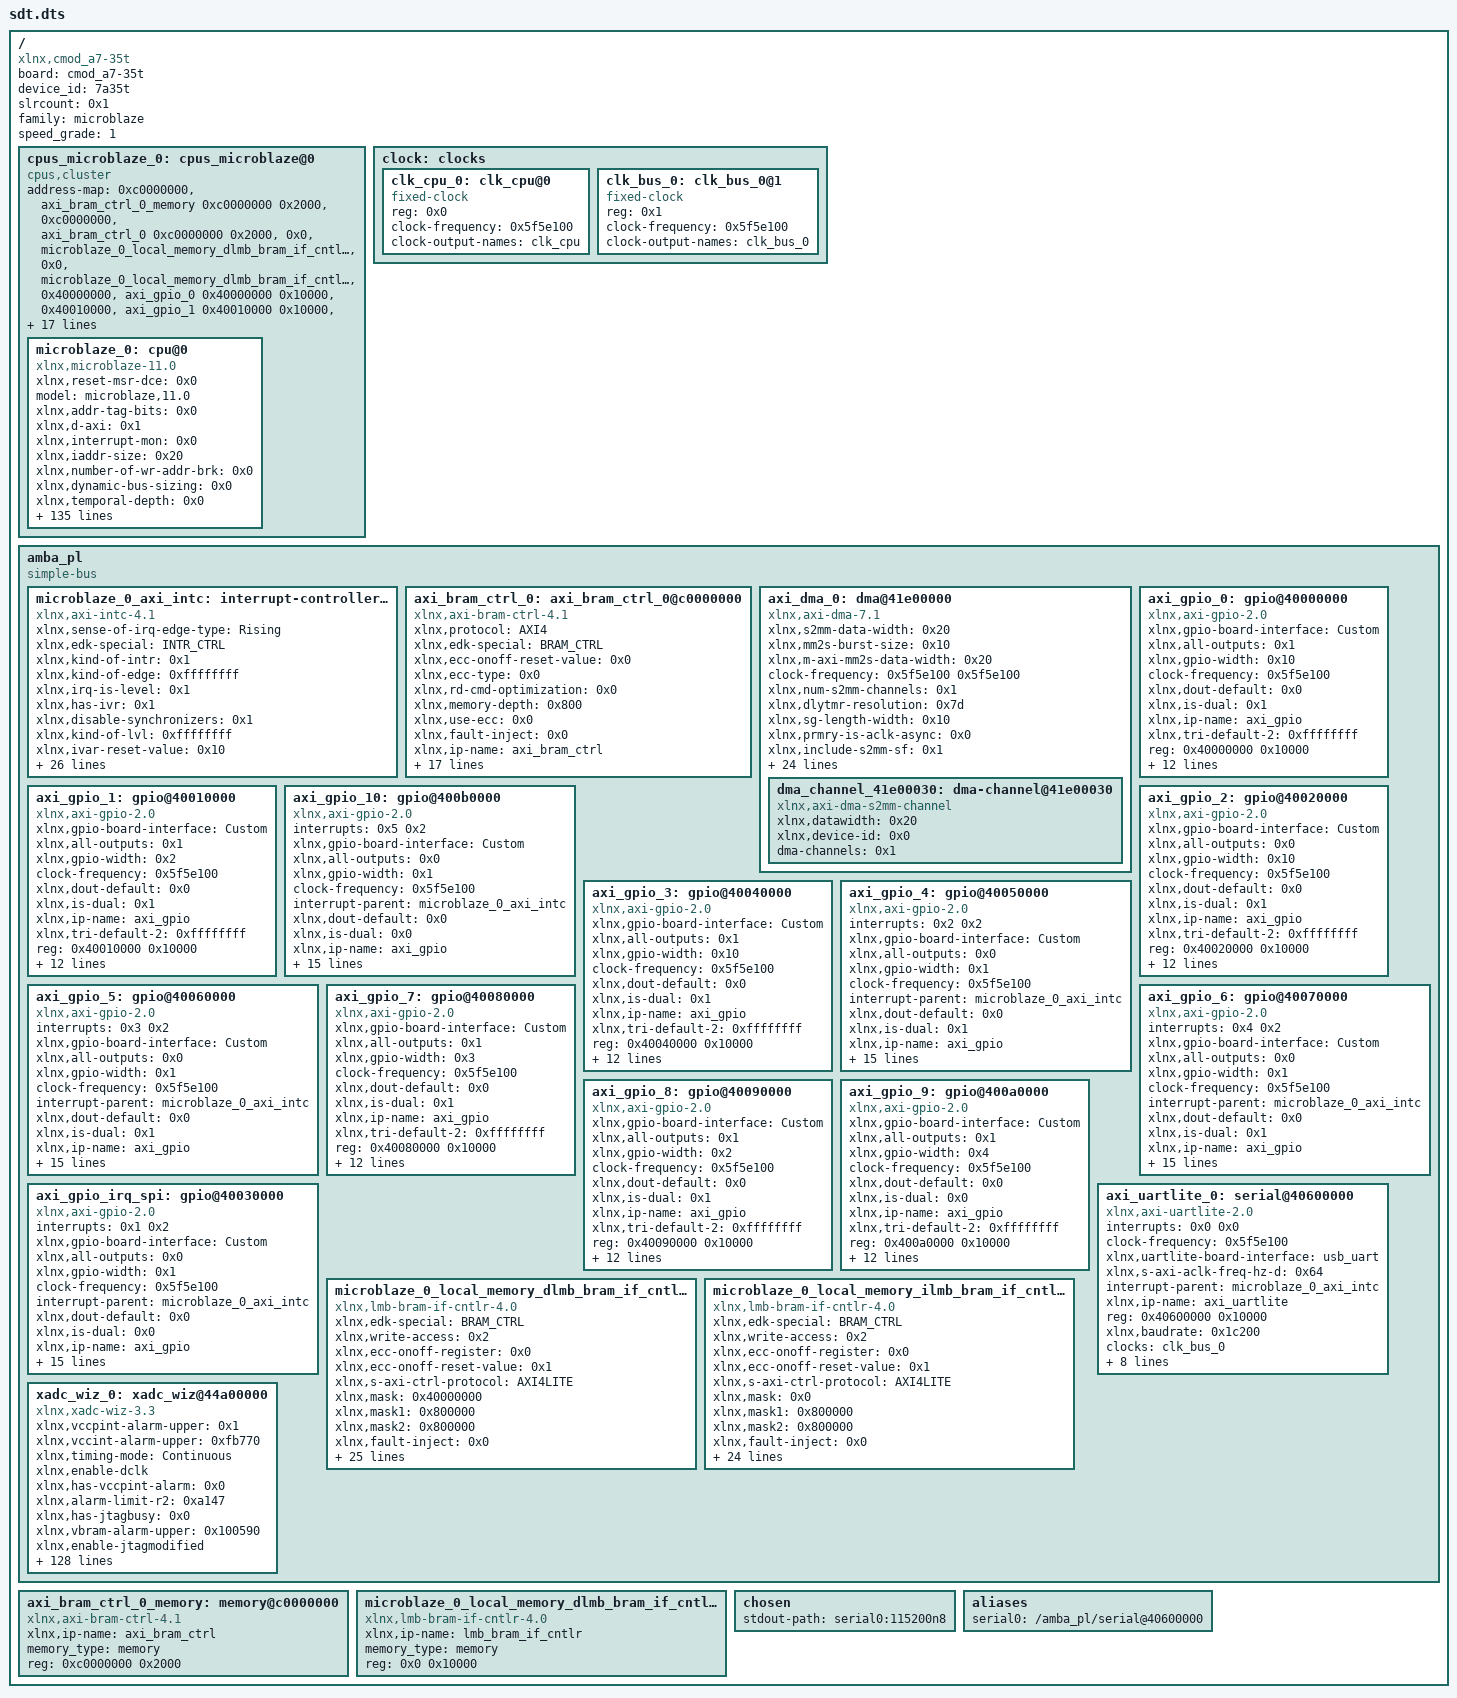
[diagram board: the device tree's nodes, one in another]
/dts-v1/;
/ {
        board = "cmod_a7-35t";
        compatible = "xlnx,cmod_a7-35t";
        device_id = "7a35t";
        #address-cells = <0x1>;
        #size-cells = <0x1>;
        slrcount = <0x1>;
        family = "microblaze";
        speed_grade = "1";

        cpus_microblaze_0: cpus_microblaze@0 {
                #cpu-mask-cells = <0x1>;
                compatible = "cpus,cluster";
                #address-cells = <0x1>;
                #size-cells = <0x0>;
                address-map = <0xc0000000 &axi_bram_ctrl_0_memory 0xc0000000 0x2000>,
                 <0xc0000000 &axi_bram_ctrl_0 0xc0000000 0x2000>,
                 <0x0 &microblaze_0_local_memory_dlmb_bram_if_cntlr_memory 0x0 0x10000>,
                 <0x0 &microblaze_0_local_memory_dlmb_bram_if_cntlr 0x0 0x10000>,
                 <0x40000000 &axi_gpio_0 0x40000000 0x10000>,
                 <0x40010000 &axi_gpio_1 0x40010000 0x10000>,
                 <0x40020000 &axi_gpio_2 0x40020000 0x10000>,
                 <0x40030000 &axi_gpio_irq_spi 0x40030000 0x10000>,
                 <0x40040000 &axi_gpio_3 0x40040000 0x10000>,
                 <0x40050000 &axi_gpio_4 0x40050000 0x10000>,
                 <0x40060000 &axi_gpio_5 0x40060000 0x10000>,
                 <0x40070000 &axi_gpio_6 0x40070000 0x10000>,
                 <0x40080000 &axi_gpio_7 0x40080000 0x10000>,
                 <0x40090000 &axi_gpio_8 0x40090000 0x10000>,
                 <0x400a0000 &axi_gpio_9 0x400a0000 0x10000>,
                 <0x400b0000 &axi_gpio_10 0x400b0000 0x10000>,
                 <0x40600000 &axi_uartlite_0 0x40600000 0x10000>,
                 <0x41200000 &microblaze_0_axi_intc 0x41200000 0x10000>,
                 <0x41e00000 &axi_dma_0 0x41e00000 0x10000>,
                 <0x44a00000 &xadc_wiz_0 0x44a00000 0x10000>;
                #ranges-address-cells = <0x1>;
                #ranges-size-cells = <0x1>;
                phandle = <0x17>;

                microblaze_0: cpu@0 {
                        xlnx,reset-msr-dce = <0x0>;
                        model = "microblaze,11.0";
                        xlnx,addr-tag-bits = <0x0>;
                        xlnx,d-axi = <0x1>;
                        xlnx,interrupt-mon = <0x0>;
                        xlnx,iaddr-size = <0x20>;
                        xlnx,number-of-wr-addr-brk = <0x0>;
                        xlnx,dynamic-bus-sizing = <0x0>;
                        xlnx,temporal-depth = <0x0>;
                        xlnx,use-interrupt = <0x2>;
                        xlnx,optimization = <0x0>;
                        xlnx,ip-axi-mon = <0x0>;
                        xlnx,ip-name = "microblaze";
                        d-cache-highaddr = <0x3fffffff>;
                        xlnx,dcache-force-tag-lutram = <0x0>;
                        xlnx,pc-width = <0x20>;
                        xlnx,interrupt-is-edge = <0x0>;
                        reg = <0x0>;
                        xlnx,async-interrupt = <0x1>;
                        xlnx,use-mmu = <0x0>;
                        xlnx,reset-msr-ee = <0x0>;
                        xlnx,icache-victims = <0x0>;
                        xlnx,use-reorder-instr = <0x1>;
                        xlnx,d-lmb-mon = <0x0>;
                        xlnx,d-lmb-protocol = <0x0>;
                        xlnx,ill-opcode-exception = <0x0>;
                        xlnx,dcache-always-used = <0x1>;
                        xlnx,use-div = <0x0>;
                        xlnx,dc-axi-mon = <0x0>;
                        xlnx,debug-trace-async-reset = <0x0>;
                        xlnx,trace = <0x0>;
                        xlnx,part = "xc7a35tcpg236-1";
                        i-cache-baseaddr = <0x0>;
                        xlnx,use-config-reset = <0x0>;
                        xlnx,pvr = <0x0>;
                        xlnx,i-lmb-mon = <0x0>;
                        xlnx,dcache-byte-size = <0x2000>;
                        xlnx,fault-tolerant = <0x0>;
                        xlnx,family = "artix7";
                        compatible = "xlnx,microblaze-11.0", "xlnx,microblaze";
                        xlnx,data-size = <0x20>;
                        xlnx,mmu-zones = <0x10>;
                        xlnx,debug-trace-size = <0x2000>;
                        xlnx,mmu-privileged-instr = <0x0>;
                        xlnx,enable-discrete-ports = <0x0>;
                        d-cache-line-size = <0x10>;
                        xlnx,d-lmb = <0x1>;
                        xlnx,sco = <0x0>;
                        xlnx,reset-msr-eip = <0x0>;
                        xlnx,debug-interface = <0x0>;
                        clock-frequency = <0x5f5e100>;
                        xlnx,use-ext-brk = <0x0>;
                        xlnx,daddr-size = <0x20>;
                        xlnx,debug-enabled = <0x1>;
                        xlnx,reset-msr-ice = <0x0>;
                        xlnx,num-sync-ff-dbg-trace-clk = <0x2>;
                        xlnx,i-lmb-protocol = <0x0>;
                        xlnx,endianness = <0x1>;
                        xlnx,fsl-exception = <0x0>;
                        i-cache-line-size = <0x10>;
                        xlnx,use-extended-fsl-instr = <0x0>;
                        xlnx,reset-msr = <0x0>;
                        xlnx,dp-axi-mon = <0x0>;
                        device_type = "cpu";
                        xlnx,branch-target-cache-size = <0x0>;
                        xlnx,dcache-use-writeback = <0x0>;
                        xlnx,div-zero-exception = <0x0>;
                        xlnx,mmu-tlb-access = <0x3>;
                        bus-handle = <0x15>;
                        xlnx,cache-byte-size = <0x2000>;
                        xlnx,pvr-user2 = <0x0>;
                        xlnx,opcode-0x0-illegal = <0x0>;
                        xlnx,icache-line-len = <0x4>;
                        xlnx,ecc-use-ce-exception = <0x0>;
                        xlnx,base-vectors = <0x0>;
                        xlnx,edk-special = "microblaze";
                        xlnx,use-dcache = <0x0>;
                        xlnx,use-barrel = <0x0>;
                        xlnx,reset-msr-bip = <0x0>;
                        xlnx,allow-dcache-wr = <0x1>;
                        xlnx,debug-external-trace = <0x0>;
                        xlnx,addr-size = <0x20>;
                        xlnx,piaddr-size = <0x20>;
                        i-cache-highaddr = <0x3fffffff>;
                        xlnx,num-sync-ff-clk-debug = <0x2>;
                        xlnx,debug-event-counters = <0x5>;
                        xlnx,fpu-exception = <0x0>;
                        xlnx,allow-icache-wr = <0x1>;
                        xlnx,g-use-exceptions = <0x0>;
                        xlnx,i-axi = <0x0>;
                        xlnx,g-template-list = <0x0>;
                        xlnx,icache-streams = <0x0>;
                        xlnx,dcache-line-len = <0x4>;
                        xlnx,num-sync-ff-clk = <0x2>;
                        xlnx,edk-iptype = "PROCESSOR";
                        xlnx,use-stack-protection = <0x0>;
                        xlnx,use-hw-mul = <0x0>;
                        xlnx,num-sync-ff-dbg-clk = <0x1>;
                        xlnx,interconnect = <0x2>;
                        xlnx,debug-latency-counters = <0x1>;
                        i-cache-size = <0x2000>;
                        xlnx,exceptions-in-delay-slots = <0x1>;
                        xlnx,use-fpu = <0x0>;
                        xlnx,reset-msr-ie = <0x0>;
                        xlnx,edge-is-positive = <0x1>;
                        xlnx,use-pcmp-instr = <0x0>;
                        xlnx,use-icache = <0x0>;
                        d-cache-size = <0x2000>;
                        xlnx,memory-ip-list = "microblaze_0_local_memory_ilmb_bram_if_cntlr_memory", "microblaze_0_local_memory_dlmb_bram_if_cntlr_memory";
                        xlnx,async-wakeup = <0x3>;
                        xlnx,use-non-secure = <0x0>;
                        xlnx,dcache-addr-tag = <0x0>;
                        xlnx,number-of-rd-addr-brk = <0x0>;
                        d-cache-baseaddr = <0x0>;
                        xlnx,area-optimized = <0x0>;
                        xlnx,avoid-primitives = <0x0>;
                        xlnx,lockstep-slave = <0x0>;
                        xlnx,use-ext-nm-brk = <0x0>;
                        xlnx,instr-size = <0x20>;
                        interrupt-handle = <0x12>;
                        xlnx,icache-always-used = <0x1>;
                        xlnx,i-lmb = <0x1>;
                        xlnx,mmu-dtlb-size = <0x4>;
                        xlnx,lockstep-select = <0x0>;
                        xlnx,lmb-data-size = <0x20>;
                        xlnx,ic-axi-mon = <0x0>;
                        xlnx,enable-conversion = <0x0>;
                        xlnx,num-sync-ff-clk-irq = <0x1>;
                        xlnx,fsl-links = <0x0>;
                        timebase-frequency = <0x5f5e100>;
                        xlnx,icache-force-tag-lutram = <0x0>;
                        xlnx,dcache-data-width = <0x0>;
                        xlnx,dcache-victims = <0x0>;
                        xlnx,use-branch-target-cache = <0x0>;
                        xlnx,debug-profile-size = <0x0>;
                        xlnx,unaligned-exceptions = <0x0>;
                        xlnx,lockstep-master = <0x0>;
                        xlnx,freq = <0x5f5e100>;
                        xlnx,number-of-pc-brk = <0x1>;
                        xlnx,mmu-itlb-size = <0x2>;
                        xlnx,imprecise-exceptions = <0x0>;
                        xlnx,use-msr-instr = <0x0>;
                        xlnx,icache-data-width = <0x0>;
                        xlnx,debug-counter-width = <0x20>;
                        phandle = <0x18>;
                };
        };

        clock: clocks {
                #address-cells = <0x1>;
                #size-cells = <0x0>;
                phandle = <0x19>;

                clk_cpu_0: clk_cpu@0 {
                        compatible = "fixed-clock";
                        reg = <0x0>;
                        clock-frequency = <0x5f5e100>;
                        clock-output-names = "clk_cpu";
                        #clock-cells = <0x0>;
                        phandle = <0x1a>;
                };

                clk_bus_0: clk_bus_0@1 {
                        compatible = "fixed-clock";
                        reg = <0x1>;
                        clock-frequency = <0x5f5e100>;
                        clock-output-names = "clk_bus_0";
                        #clock-cells = <0x0>;
                        phandle = <0x16>;
                };
        };

        amba_pl: amba_pl {
                ranges;
                compatible = "simple-bus";
                #address-cells = <0x1>;
                #size-cells = <0x1>;
                phandle = <0x15>;

                microblaze_0_axi_intc: interrupt-controller@41200000 {
                        #interrupt-cells = <0x2>;
                        xlnx,sense-of-irq-edge-type = "Rising";
                        xlnx,edk-special = "INTR_CTRL";
                        xlnx,kind-of-intr = <0x1>;
                        xlnx,kind-of-edge = <0xffffffff>;
                        xlnx,irq-is-level = <0x1>;
                        xlnx,has-ivr = <0x1>;
                        compatible = "xlnx,axi-intc-4.1", "xlnx,xps-intc-1.00.a";
                        xlnx,disable-synchronizers = <0x1>;
                        xlnx,kind-of-lvl = <0xffffffff>;
                        xlnx,ivar-reset-value = <0x10>;
                        xlnx,irq-active = <0x1>;
                        xlnx,en-cascade-mode = <0x0>;
                        xlnx,ip-name = "axi_intc";
                        xlnx,has-ilr = <0x0>;
                        reg = <0x41200000 0x10000>;
                        xlnx,addr-width = <0x20>;
                        xlnx,s-axi-aclk-freq-mhz = <0x64>;
                        xlnx,num-sw-intr = <0x0>;
                        xlnx,irq-connection = <0x0>;
                        xlnx,num-intr-inputs = <0x6>;
                        xlnx,has-sie = <0x1>;
                        xlnx,enable-async = <0x0>;
                        xlnx,has-cie = <0x1>;
                        xlnx,num-sync-ff = <0x2>;
                        xlnx,edk-iptype = "PERIPHERAL";
                        xlnx,mb-clk-not-connected = <0x1>;
                        xlnx,has-ipr = <0x1>;
                        xlnx,sense-of-irq-level-type = "Active_High";
                        xlnx,cascade-master = <0x0>;
                        xlnx,processor-clk-freq-mhz = <0x64>;
                        status = "okay";
                        xlnx,is-fast = <0x1>;
                        xlnx,has-fast = <0x1>;
                        xlnx,ivar-rst-val = <0x10>;
                        interrupt-controller;
                        xlnx,async-intr = <0xffffffc0>;
                        xlnx,name = "microblaze_0_axi_intc";
                        phandle = <0x12>;
                };

                axi_bram_ctrl_0: axi_bram_ctrl_0@c0000000 {
                        xlnx,protocol = "AXI4";
                        xlnx,edk-special = "BRAM_CTRL";
                        compatible = "xlnx,axi-bram-ctrl-4.1", "xlnx,axi-bram-ctrl";
                        xlnx,ecc-onoff-reset-value = <0x0>;
                        xlnx,ecc-type = <0x0>;
                        xlnx,rd-cmd-optimization = <0x0>;
                        xlnx,memory-depth = <0x800>;
                        xlnx,use-ecc = <0x0>;
                        xlnx,fault-inject = <0x0>;
                        xlnx,ip-name = "axi_bram_ctrl";
                        reg = <0xc0000000 0x2000>;
                        xlnx,bmg-instance = "EXTERNAL";
                        xlnx,s-axi-ctrl-addr-width = <0x20>;
                        xlnx,read-latency = <0x1>;
                        xlnx,id-width = <0x0>;
                        xlnx,s-axi-supports-narrow-burst = <0x0>;
                        xlnx,supports-narrow-burst = <0x0>;
                        xlnx,single-port-bram = <0x0>;
                        xlnx,ecc = <0x0>;
                        xlnx,edk-iptype = "PERIPHERAL";
                        status = "okay";
                        xlnx,data-width = <0x20>;
                        xlnx,bram-addr-width = <0xb>;
                        xlnx,bram-inst-mode = "EXTERNAL";
                        xlnx,s-axi-ctrl-data-width = <0x20>;
                        xlnx,mem-depth = <0x800>;
                        xlnx,s-axi-id-width = <0x1>;
                        xlnx,name = "axi_bram_ctrl_0";
                        phandle = <0x2>;
                };

                axi_dma_0: dma@41e00000 {
                        compatible = "xlnx,axi-dma-7.1", "xlnx,axi-dma-1.00.a";
                        xlnx,s2mm-data-width = <0x20>;
                        xlnx,mm2s-burst-size = <0x10>;
                        xlnx,m-axi-mm2s-data-width = <0x20>;
                        clock-frequency = <0x5f5e100 0x5f5e100>;
                        xlnx,num-s2mm-channels = <0x1>;
                        xlnx,dlytmr-resolution = <0x7d>;
                        xlnx,sg-length-width = <0x10>;
                        xlnx,prmry-is-aclk-async = <0x0>;
                        xlnx,include-s2mm-sf = <0x1>;
                        #dma-cells = <0x1>;
                        xlnx,ip-name = "axi_dma";
                        xlnx,single-interface = <0x0>;
                        xlnx,sg-include-stscntrl-strm = <0x0>;
                        xlnx,include-s2mm-dre = <0x0>;
                        reg = <0x41e00000 0x10000>;
                        xlnx,addr-width = <0x20>;
                        xlnx,include-s2mm = <0x1>;
                        clocks = <&clk_bus_0>,
                         <&clk_bus_0>;
                        xlnx,s-axis-s2mm-tdata-width = <0x20>;
                        xlnx,micro-dma = <0x0>;
                        xlnx,increase-throughput = <0x0>;
                        xlnx,mm2s-data-width = <0x20>;
                        xlnx,addrwidth = <0x20>;
                        xlnx,sg-use-stsapp-length = <0x0>;
                        xlnx,m-axis-mm2s-tdata-width = <0x20>;
                        xlnx,edk-iptype = "PERIPHERAL";
                        xlnx,s2mm-burst-size = <0x10>;
                        xlnx,m-axi-s2mm-data-width = <0x20>;
                        xlnx,num-mm2s-channels = <0x1>;
                        xlnx,enable-multi-channel = <0x0>;
                        status = "okay";
                        xlnx,include-mm2s-sf = <0x1>;
                        clock-names = "s_axi_lite_aclk", "m_axi_sg_aclk", "m_axi_s2mm_aclk";
                        xlnx,include-mm2s = <0x0>;
                        xlnx,include-mm2s-dre = <0x0>;
                        xlnx,name = "axi_dma_0";
                        phandle = <0x13>;

                        dma_channel_41e00030: dma-channel@41e00030 {
                                xlnx,datawidth = <0x20>;
                                xlnx,device-id = <0x0>;
                                compatible = "xlnx,axi-dma-s2mm-channel";
                                dma-channels = <0x1>;
                                phandle = <0x1b>;
                        };
                };

                axi_gpio_0: gpio@40000000 {
                        xlnx,gpio-board-interface = "Custom";
                        compatible = "xlnx,axi-gpio-2.0", "xlnx,xps-gpio-1.00.a";
                        xlnx,all-outputs = <0x1>;
                        #gpio-cells = <0x2>;
                        xlnx,gpio-width = <0x10>;
                        clock-frequency = <0x5f5e100>;
                        xlnx,dout-default = <0x0>;
                        xlnx,is-dual = <0x1>;
                        xlnx,ip-name = "axi_gpio";
                        xlnx,tri-default-2 = <0xffffffff>;
                        reg = <0x40000000 0x10000>;
                        xlnx,all-inputs-2 = <0x0>;
                        clocks = <&clk_bus_0>;
                        xlnx,all-outputs-2 = <0x1>;
                        gpio-controller;
                        xlnx,interrupt-present = <0x0>;
                        xlnx,gpio2-board-interface = "Custom";
                        xlnx,edk-iptype = "PERIPHERAL";
                        xlnx,dout-default-2 = <0x0>;
                        status = "okay";
                        xlnx,gpio2-width = <0x10>;
                        clock-names = "s_axi_aclk";
                        xlnx,tri-default = <0xffffffff>;
                        xlnx,name = "axi_gpio_0";
                        xlnx,all-inputs = <0x0>;
                        phandle = <0x5>;
                };

                axi_gpio_1: gpio@40010000 {
                        xlnx,gpio-board-interface = "Custom";
                        compatible = "xlnx,axi-gpio-2.0", "xlnx,xps-gpio-1.00.a";
                        xlnx,all-outputs = <0x1>;
                        #gpio-cells = <0x2>;
                        xlnx,gpio-width = <0x2>;
                        clock-frequency = <0x5f5e100>;
                        xlnx,dout-default = <0x0>;
                        xlnx,is-dual = <0x1>;
                        xlnx,ip-name = "axi_gpio";
                        xlnx,tri-default-2 = <0xffffffff>;
                        reg = <0x40010000 0x10000>;
                        xlnx,all-inputs-2 = <0x0>;
                        clocks = <&clk_bus_0>;
                        xlnx,all-outputs-2 = <0x1>;
                        gpio-controller;
                        xlnx,interrupt-present = <0x0>;
                        xlnx,gpio2-board-interface = "Custom";
                        xlnx,edk-iptype = "PERIPHERAL";
                        xlnx,dout-default-2 = <0x0>;
                        status = "okay";
                        xlnx,gpio2-width = <0x2>;
                        clock-names = "s_axi_aclk";
                        xlnx,tri-default = <0xffffffff>;
                        xlnx,name = "axi_gpio_1";
                        xlnx,all-inputs = <0x0>;
                        phandle = <0x6>;
                };

                axi_gpio_10: gpio@400b0000 {
                        #interrupt-cells = <0x2>;
                        interrupts = <0x5 0x2>;
                        xlnx,gpio-board-interface = "Custom";
                        compatible = "xlnx,axi-gpio-2.0", "xlnx,xps-gpio-1.00.a";
                        xlnx,all-outputs = <0x0>;
                        #gpio-cells = <0x2>;
                        xlnx,gpio-width = <0x1>;
                        clock-frequency = <0x5f5e100>;
                        interrupt-parent = <&microblaze_0_axi_intc>;
                        xlnx,dout-default = <0x0>;
                        xlnx,is-dual = <0x0>;
                        xlnx,ip-name = "axi_gpio";
                        xlnx,tri-default-2 = <0xffffffff>;
                        reg = <0x400b0000 0x10000>;
                        xlnx,all-inputs-2 = <0x0>;
                        clocks = <&clk_bus_0>;
                        xlnx,all-outputs-2 = <0x0>;
                        gpio-controller;
                        xlnx,interrupt-present = <0x1>;
                        xlnx,gpio2-board-interface = "Custom";
                        xlnx,edk-iptype = "PERIPHERAL";
                        xlnx,dout-default-2 = <0x0>;
                        status = "okay";
                        xlnx,gpio2-width = <0x20>;
                        clock-names = "s_axi_aclk";
                        interrupt-controller;
                        interrupt-names = "ip2intc_irpt";
                        xlnx,tri-default = <0xffffffff>;
                        xlnx,name = "axi_gpio_10";
                        xlnx,all-inputs = <0x1>;
                        phandle = <0x10>;
                };

                axi_gpio_2: gpio@40020000 {
                        xlnx,gpio-board-interface = "Custom";
                        compatible = "xlnx,axi-gpio-2.0", "xlnx,xps-gpio-1.00.a";
                        xlnx,all-outputs = <0x0>;
                        #gpio-cells = <0x2>;
                        xlnx,gpio-width = <0x10>;
                        clock-frequency = <0x5f5e100>;
                        xlnx,dout-default = <0x0>;
                        xlnx,is-dual = <0x1>;
                        xlnx,ip-name = "axi_gpio";
                        xlnx,tri-default-2 = <0xffffffff>;
                        reg = <0x40020000 0x10000>;
                        xlnx,all-inputs-2 = <0x0>;
                        clocks = <&clk_bus_0>;
                        xlnx,all-outputs-2 = <0x1>;
                        gpio-controller;
                        xlnx,interrupt-present = <0x0>;
                        xlnx,gpio2-board-interface = "Custom";
                        xlnx,edk-iptype = "PERIPHERAL";
                        xlnx,dout-default-2 = <0x0>;
                        status = "okay";
                        xlnx,gpio2-width = <0x10>;
                        clock-names = "s_axi_aclk";
                        xlnx,tri-default = <0xffffffff>;
                        xlnx,name = "axi_gpio_2";
                        xlnx,all-inputs = <0x1>;
                        phandle = <0x7>;
                };

                axi_gpio_3: gpio@40040000 {
                        xlnx,gpio-board-interface = "Custom";
                        compatible = "xlnx,axi-gpio-2.0", "xlnx,xps-gpio-1.00.a";
                        xlnx,all-outputs = <0x1>;
                        #gpio-cells = <0x2>;
                        xlnx,gpio-width = <0x10>;
                        clock-frequency = <0x5f5e100>;
                        xlnx,dout-default = <0x0>;
                        xlnx,is-dual = <0x1>;
                        xlnx,ip-name = "axi_gpio";
                        xlnx,tri-default-2 = <0xffffffff>;
                        reg = <0x40040000 0x10000>;
                        xlnx,all-inputs-2 = <0x0>;
                        clocks = <&clk_bus_0>;
                        xlnx,all-outputs-2 = <0x1>;
                        gpio-controller;
                        xlnx,interrupt-present = <0x0>;
                        xlnx,gpio2-board-interface = "Custom";
                        xlnx,edk-iptype = "PERIPHERAL";
                        xlnx,dout-default-2 = <0x0>;
                        status = "okay";
                        xlnx,gpio2-width = <0x10>;
                        clock-names = "s_axi_aclk";
                        xlnx,tri-default = <0xffffffff>;
                        xlnx,name = "axi_gpio_3";
                        xlnx,all-inputs = <0x0>;
                        phandle = <0x9>;
                };

                axi_gpio_4: gpio@40050000 {
                        #interrupt-cells = <0x2>;
                        interrupts = <0x2 0x2>;
                        xlnx,gpio-board-interface = "Custom";
                        compatible = "xlnx,axi-gpio-2.0", "xlnx,xps-gpio-1.00.a";
                        xlnx,all-outputs = <0x0>;
                        #gpio-cells = <0x2>;
                        xlnx,gpio-width = <0x1>;
                        clock-frequency = <0x5f5e100>;
                        interrupt-parent = <&microblaze_0_axi_intc>;
                        xlnx,dout-default = <0x0>;
                        xlnx,is-dual = <0x1>;
                        xlnx,ip-name = "axi_gpio";
                        xlnx,tri-default-2 = <0xffffffff>;
                        reg = <0x40050000 0x10000>;
                        xlnx,all-inputs-2 = <0x1>;
                        clocks = <&clk_bus_0>;
                        xlnx,all-outputs-2 = <0x0>;
                        gpio-controller;
                        xlnx,interrupt-present = <0x1>;
                        xlnx,gpio2-board-interface = "Custom";
                        xlnx,edk-iptype = "PERIPHERAL";
                        xlnx,dout-default-2 = <0x0>;
                        status = "okay";
                        xlnx,gpio2-width = <0x1>;
                        clock-names = "s_axi_aclk";
                        interrupt-controller;
                        interrupt-names = "ip2intc_irpt";
                        xlnx,tri-default = <0xffffffff>;
                        xlnx,name = "axi_gpio_4";
                        xlnx,all-inputs = <0x1>;
                        phandle = <0xa>;
                };

                axi_gpio_5: gpio@40060000 {
                        #interrupt-cells = <0x2>;
                        interrupts = <0x3 0x2>;
                        xlnx,gpio-board-interface = "Custom";
                        compatible = "xlnx,axi-gpio-2.0", "xlnx,xps-gpio-1.00.a";
                        xlnx,all-outputs = <0x0>;
                        #gpio-cells = <0x2>;
                        xlnx,gpio-width = <0x1>;
                        clock-frequency = <0x5f5e100>;
                        interrupt-parent = <&microblaze_0_axi_intc>;
                        xlnx,dout-default = <0x0>;
                        xlnx,is-dual = <0x1>;
                        xlnx,ip-name = "axi_gpio";
                        xlnx,tri-default-2 = <0xffffffff>;
                        reg = <0x40060000 0x10000>;
                        xlnx,all-inputs-2 = <0x1>;
                        clocks = <&clk_bus_0>;
                        xlnx,all-outputs-2 = <0x0>;
                        gpio-controller;
                        xlnx,interrupt-present = <0x1>;
                        xlnx,gpio2-board-interface = "Custom";
                        xlnx,edk-iptype = "PERIPHERAL";
                        xlnx,dout-default-2 = <0x0>;
                        status = "okay";
                        xlnx,gpio2-width = <0x1>;
                        clock-names = "s_axi_aclk";
                        interrupt-controller;
                        interrupt-names = "ip2intc_irpt";
                        xlnx,tri-default = <0xffffffff>;
                        xlnx,name = "axi_gpio_5";
                        xlnx,all-inputs = <0x1>;
                        phandle = <0xb>;
                };

                axi_gpio_6: gpio@40070000 {
                        #interrupt-cells = <0x2>;
                        interrupts = <0x4 0x2>;
                        xlnx,gpio-board-interface = "Custom";
                        compatible = "xlnx,axi-gpio-2.0", "xlnx,xps-gpio-1.00.a";
                        xlnx,all-outputs = <0x0>;
                        #gpio-cells = <0x2>;
                        xlnx,gpio-width = <0x1>;
                        clock-frequency = <0x5f5e100>;
                        interrupt-parent = <&microblaze_0_axi_intc>;
                        xlnx,dout-default = <0x0>;
                        xlnx,is-dual = <0x1>;
                        xlnx,ip-name = "axi_gpio";
                        xlnx,tri-default-2 = <0xffffffff>;
                        reg = <0x40070000 0x10000>;
                        xlnx,all-inputs-2 = <0x1>;
                        clocks = <&clk_bus_0>;
                        xlnx,all-outputs-2 = <0x0>;
                        gpio-controller;
                        xlnx,interrupt-present = <0x1>;
                        xlnx,gpio2-board-interface = "Custom";
                        xlnx,edk-iptype = "PERIPHERAL";
                        xlnx,dout-default-2 = <0x0>;
                        status = "okay";
                        xlnx,gpio2-width = <0x1>;
                        clock-names = "s_axi_aclk";
                        interrupt-controller;
                        interrupt-names = "ip2intc_irpt";
                        xlnx,tri-default = <0xffffffff>;
                        xlnx,name = "axi_gpio_6";
                        xlnx,all-inputs = <0x1>;
                        phandle = <0xc>;
                };

                axi_gpio_7: gpio@40080000 {
                        xlnx,gpio-board-interface = "Custom";
                        compatible = "xlnx,axi-gpio-2.0", "xlnx,xps-gpio-1.00.a";
                        xlnx,all-outputs = <0x1>;
                        #gpio-cells = <0x2>;
                        xlnx,gpio-width = <0x3>;
                        clock-frequency = <0x5f5e100>;
                        xlnx,dout-default = <0x0>;
                        xlnx,is-dual = <0x1>;
                        xlnx,ip-name = "axi_gpio";
                        xlnx,tri-default-2 = <0xffffffff>;
                        reg = <0x40080000 0x10000>;
                        xlnx,all-inputs-2 = <0x0>;
                        clocks = <&clk_bus_0>;
                        xlnx,all-outputs-2 = <0x1>;
                        gpio-controller;
                        xlnx,interrupt-present = <0x0>;
                        xlnx,gpio2-board-interface = "Custom";
                        xlnx,edk-iptype = "PERIPHERAL";
                        xlnx,dout-default-2 = <0x0>;
                        status = "okay";
                        xlnx,gpio2-width = <0x3>;
                        clock-names = "s_axi_aclk";
                        xlnx,tri-default = <0xffffffff>;
                        xlnx,name = "axi_gpio_7";
                        xlnx,all-inputs = <0x0>;
                        phandle = <0xd>;
                };

                axi_gpio_8: gpio@40090000 {
                        xlnx,gpio-board-interface = "Custom";
                        compatible = "xlnx,axi-gpio-2.0", "xlnx,xps-gpio-1.00.a";
                        xlnx,all-outputs = <0x1>;
                        #gpio-cells = <0x2>;
                        xlnx,gpio-width = <0x2>;
                        clock-frequency = <0x5f5e100>;
                        xlnx,dout-default = <0x0>;
                        xlnx,is-dual = <0x1>;
                        xlnx,ip-name = "axi_gpio";
                        xlnx,tri-default-2 = <0xffffffff>;
                        reg = <0x40090000 0x10000>;
                        xlnx,all-inputs-2 = <0x0>;
                        clocks = <&clk_bus_0>;
                        xlnx,all-outputs-2 = <0x1>;
                        gpio-controller;
                        xlnx,interrupt-present = <0x0>;
                        xlnx,gpio2-board-interface = "Custom";
                        xlnx,edk-iptype = "PERIPHERAL";
                        xlnx,dout-default-2 = <0x0>;
                        status = "okay";
                        xlnx,gpio2-width = <0x2>;
                        clock-names = "s_axi_aclk";
                        xlnx,tri-default = <0xffffffff>;
                        xlnx,name = "axi_gpio_8";
                        xlnx,all-inputs = <0x0>;
                        phandle = <0xe>;
                };

                axi_gpio_9: gpio@400a0000 {
                        xlnx,gpio-board-interface = "Custom";
                        compatible = "xlnx,axi-gpio-2.0", "xlnx,xps-gpio-1.00.a";
                        xlnx,all-outputs = <0x1>;
                        #gpio-cells = <0x2>;
                        xlnx,gpio-width = <0x4>;
                        clock-frequency = <0x5f5e100>;
                        xlnx,dout-default = <0x0>;
                        xlnx,is-dual = <0x0>;
                        xlnx,ip-name = "axi_gpio";
                        xlnx,tri-default-2 = <0xffffffff>;
                        reg = <0x400a0000 0x10000>;
                        xlnx,all-inputs-2 = <0x0>;
                        clocks = <&clk_bus_0>;
                        xlnx,all-outputs-2 = <0x0>;
                        gpio-controller;
                        xlnx,interrupt-present = <0x0>;
                        xlnx,gpio2-board-interface = "Custom";
                        xlnx,edk-iptype = "PERIPHERAL";
                        xlnx,dout-default-2 = <0x0>;
                        status = "okay";
                        xlnx,gpio2-width = <0x20>;
                        clock-names = "s_axi_aclk";
                        xlnx,tri-default = <0xffffffff>;
                        xlnx,name = "axi_gpio_9";
                        xlnx,all-inputs = <0x0>;
                        phandle = <0xf>;
                };

                axi_gpio_irq_spi: gpio@40030000 {
                        #interrupt-cells = <0x2>;
                        interrupts = <0x1 0x2>;
                        xlnx,gpio-board-interface = "Custom";
                        compatible = "xlnx,axi-gpio-2.0", "xlnx,xps-gpio-1.00.a";
                        xlnx,all-outputs = <0x0>;
                        #gpio-cells = <0x2>;
                        xlnx,gpio-width = <0x1>;
                        clock-frequency = <0x5f5e100>;
                        interrupt-parent = <&microblaze_0_axi_intc>;
                        xlnx,dout-default = <0x0>;
                        xlnx,is-dual = <0x0>;
                        xlnx,ip-name = "axi_gpio";
                        xlnx,tri-default-2 = <0xffffffff>;
                        reg = <0x40030000 0x10000>;
                        xlnx,all-inputs-2 = <0x0>;
                        clocks = <&clk_bus_0>;
                        xlnx,all-outputs-2 = <0x0>;
                        gpio-controller;
                        xlnx,interrupt-present = <0x1>;
                        xlnx,gpio2-board-interface = "Custom";
                        xlnx,edk-iptype = "PERIPHERAL";
                        xlnx,dout-default-2 = <0x0>;
                        status = "okay";
                        xlnx,gpio2-width = <0x20>;
                        clock-names = "s_axi_aclk";
                        interrupt-controller;
                        interrupt-names = "ip2intc_irpt";
                        xlnx,tri-default = <0xffffffff>;
                        xlnx,name = "axi_gpio_irq_spi";
                        xlnx,all-inputs = <0x1>;
                        phandle = <0x8>;
                };

                axi_uartlite_0: serial@40600000 {
                        interrupts = <0x0 0x0>;
                        compatible = "xlnx,axi-uartlite-2.0", "xlnx,xps-uartlite-1.00.a";
                        clock-frequency = <0x5f5e100>;
                        xlnx,uartlite-board-interface = "usb_uart";
                        xlnx,s-axi-aclk-freq-hz-d = <0x64>;
                        interrupt-parent = <&microblaze_0_axi_intc>;
                        xlnx,ip-name = "axi_uartlite";
                        reg = <0x40600000 0x10000>;
                        xlnx,baudrate = <0x1c200>;
                        clocks = <&clk_bus_0>;
                        current-speed = <0x1c200>;
                        xlnx,use-parity = <0x0>;
                        xlnx,edk-iptype = "PERIPHERAL";
                        xlnx,odd-parity = <0x0>;
                        status = "okay";
                        xlnx,use-board-flow;
                        interrupt-names = "interrupt";
                        xlnx,name = "axi_uartlite_0";
                        xlnx,data-bits = <0x8>;
                        xlnx,parity = "No_Parity";
                        phandle = <0x11>;
                };

                microblaze_0_local_memory_dlmb_bram_if_cntlr: lmb_bram_if_cntlr@0 {
                        xlnx,edk-special = "BRAM_CTRL";
                        xlnx,write-access = <0x2>;
                        compatible = "xlnx,lmb-bram-if-cntlr-4.0", "xlnx,axi-bram-ctrl";
                        xlnx,ecc-onoff-register = <0x0>;
                        xlnx,ecc-onoff-reset-value = <0x1>;
                        xlnx,s-axi-ctrl-protocol = "AXI4LITE";
                        xlnx,mask = <0x40000000>;
                        xlnx,mask1 = <0x800000>;
                        xlnx,mask2 = <0x800000>;
                        xlnx,fault-inject = <0x0>;
                        xlnx,mask3 = <0x800000>;
                        xlnx,ip-name = "lmb_bram_if_cntlr";
                        xlnx,arbitration = <0x0>;
                        xlnx,num-lmb = <0x1>;
                        xlnx,mask4 = <0x800000>;
                        reg = <0x0 0x10000>;
                        xlnx,s-axi-ctrl-addr-width = <0x20>;
                        xlnx,mask5 = <0x800000>;
                        xlnx,ecc-status-registers = <0x0>;
                        xlnx,mask6 = <0x800000>;
                        xlnx,lmb-protocol = <0x0>;
                        xlnx,ce-counter-width = <0x0>;
                        xlnx,mask7 = <0x800000>;
                        xlnx,ecc = <0x0>;
                        xlnx,edk-iptype = "PERIPHERAL";
                        xlnx,lmb-dwidth = <0x20>;
                        xlnx,interconnect = <0x0>;
                        xlnx,ce-failing-registers = <0x0>;
                        xlnx,ue-failing-registers = <0x0>;
                        status = "okay";
                        xlnx,data-width = <0x20>;
                        xlnx,s-axi-ctrl-data-width = <0x20>;
                        xlnx,bram-awidth = <0x20>;
                        xlnx,lmb-awidth = <0x20>;
                        xlnx,name = "microblaze_0_local_memory_dlmb_bram_if_cntlr";
                        phandle = <0x4>;
                };

                microblaze_0_local_memory_ilmb_bram_if_cntlr: lmb_bram_if_cntlr@1 {
                        xlnx,edk-special = "BRAM_CTRL";
                        xlnx,write-access = <0x2>;
                        compatible = "xlnx,lmb-bram-if-cntlr-4.0", "xlnx,axi-bram-ctrl";
                        xlnx,ecc-onoff-register = <0x0>;
                        xlnx,ecc-onoff-reset-value = <0x1>;
                        xlnx,s-axi-ctrl-protocol = "AXI4LITE";
                        xlnx,mask = <0x0>;
                        xlnx,mask1 = <0x800000>;
                        xlnx,mask2 = <0x800000>;
                        xlnx,fault-inject = <0x0>;
                        xlnx,mask3 = <0x800000>;
                        xlnx,ip-name = "lmb_bram_if_cntlr";
                        xlnx,arbitration = <0x0>;
                        xlnx,num-lmb = <0x1>;
                        xlnx,mask4 = <0x800000>;
                        reg = <0x0 0x10000>;
                        xlnx,s-axi-ctrl-addr-width = <0x20>;
                        xlnx,mask5 = <0x800000>;
                        xlnx,ecc-status-registers = <0x0>;
                        xlnx,mask6 = <0x800000>;
                        xlnx,lmb-protocol = <0x0>;
                        xlnx,ce-counter-width = <0x0>;
                        xlnx,mask7 = <0x800000>;
                        xlnx,ecc = <0x0>;
                        xlnx,edk-iptype = "PERIPHERAL";
                        xlnx,lmb-dwidth = <0x20>;
                        xlnx,interconnect = <0x0>;
                        xlnx,ce-failing-registers = <0x0>;
                        xlnx,ue-failing-registers = <0x0>;
                        status = "okay";
                        xlnx,s-axi-ctrl-data-width = <0x20>;
                        xlnx,bram-awidth = <0x20>;
                        xlnx,lmb-awidth = <0x20>;
                        xlnx,name = "microblaze_0_local_memory_ilmb_bram_if_cntlr";
                        phandle = <0x1c>;
                };

                xadc_wiz_0: xadc_wiz@44a00000 {
                        xlnx,vccpint-alarm-upper = <0x1>;
                        xlnx,vccint-alarm-upper = <0xfb770>;
                        xlnx,timing-mode = "Continuous";
                        xlnx,enable-dclk;
                        xlnx,has-vccpint-alarm = <0x0>;
                        xlnx,alarm-limit-r2 = <0xa147>;
                        xlnx,has-jtagbusy = <0x0>;
                        xlnx,vbram-alarm-upper = <0x100590>;
                        xlnx,enable-jtagmodified;
                        xlnx,has-vbram-alarm = <0x0>;
                        xlnx,alarm-limit-r3 = <0xca33>;
                        xlnx,has-axi = <0x1>;
                        xlnx,vaux0 = <0x0>;
                        xlnx,alarm-limit-r4 = <0xa93a>;
                        xlnx,has-busy = <0x1>;
                        xlnx,ot-alarm;
                        xlnx,enable-channel;
                        xlnx,vaux1 = <0x0>;
                        xlnx,has-vccaux-alarm = <0x1>;
                        xlnx,alarm-limit-r5 = <0x52c6>;
                        xlnx,dclk-frequency = <0x64>;
                        xlnx,vaux2 = <0x0>;
                        xlnx,alarm-limit-r6 = <0x9555>;
                        xlnx,vaux3 = <0x0>;
                        xlnx,ip-name = "xadc_wiz";
                        xlnx,alarm-limit-r7 = <0xae4e>;
                        xlnx,configuration-r0 = <0x114>;
                        xlnx,has-drp = <0x0>;
                        xlnx,vaux4 = <0x1>;
                        xlnx,sim-file-rel-path = "./";
                        reg = <0x44a00000 0x10000>;
                        xlnx,alarm-limit-r8 = <0x5999>;
                        xlnx,configuration-r1 = <0x31a0>;
                        xlnx,external-mux-channel = "VP_VN";
                        xlnx,vccint-alarm;
                        xlnx,temperature-alarm-trigger = <0x55>;
                        xlnx,vaux5 = <0x0>;
                        xlnx,alarm-limit-r9 = <0x5111>;
                        xlnx,configuration-r2 = <0x400>;
                        xlnx,has-jtaglocked = <0x0>;
                        xlnx,vaux6 = <0x0>;
                        xlnx,vaux7 = <0x0>;
                        xlnx,user-temp-alarm;
                        xlnx,vaux8 = <0x0>;
                        xlnx,vaux9 = <0x0>;
                        xlnx,vaux10 = <0x0>;
                        xlnx,has-vn = <0x1>;
                        xlnx,has-vccpaux-alarm = <0x0>;
                        xlnx,acquisition-time = <0xa>;
                        xlnx,vaux11 = <0x0>;
                        xlnx,has-temp-bus = <0x0>;
                        xlnx,xadc-starup-selection = "single_channel";
                        xlnx,enable-busy;
                        xlnx,data-width = <0x20>;
                        xlnx,vaux12 = <0x0>;
                        xlnx,sim-file-sel = "Default";
                        xlnx,has-vp = <0x1>;
                        xlnx,ip-type = <0x0>;
                        xlnx,temperature-alarm-ot-reset = <0x46>;
                        xlnx,vaux13 = <0x0>;
                        xlnx,enable-convst;
                        xlnx,vaux14 = <0x0>;
                        xlnx,vccpaux-alarm-lower = <0x1a17b0>;
                        xlnx,vccaux-alarm-lower = <0x1ab3f0>;
                        xlnx,vaux15 = <0x0>;
                        compatible = "xlnx,xadc-wiz-3.3", "xlnx,axi-xadc-1.00.a";
                        xlnx,has-external-mux = <0x0>;
                        xlnx,vccaux-alarm;
                        xlnx,sampling-rate = <0xdf 0xe0288f62>;
                        xlnx,has-reset = <0x0>;
                        xlnx,adc-conversion-rate = <0x3e8>;
                        clock-frequency = <0x5f5e100>;
                        xlnx,vccddro-alarm-lower = <0x118c30>;
                        xlnx,enable-calibration-averaging;
                        xlnx,has-user-temp-alarm = <0x1>;
                        xlnx,enable-axi4stream;
                        xlnx,has-ot-alarm = <0x1>;
                        xlnx,has-convst = <0x0>;
                        xlnx,single-channel-selection = "VAUXP4_VAUXN4";
                        xlnx,startup-channel-selection = "single_channel";
                        xlnx,interface-selection = "Enable_AXI";
                        xlnx,vccpaux-alarm-upper = <0x1b7740>;
                        xlnx,vccaux-alarm-upper = <0x1cd6d0>;
                        status = "okay";
                        xlnx,sensor-offset-and-gain-calibration;
                        xlnx,vccddro-alarm-upper = <0x1312d0>;
                        xlnx,name = "xadc_wiz_0";
                        xlnx,external-mux = "none";
                        xlnx,enable-eoc;
                        xlnx,enable-jtaglocked;
                        xlnx,sim-file-name = "design";
                        xlnx,temperature-alarm-reset = <0x3c>;
                        xlnx,addr-width = <0x20>;
                        clocks = <&clk_bus_0>;
                        xlnx,alarm-limit-r10 = <0x5555>;
                        xlnx,alarm-limit-r11 = <0x5111>;
                        xlnx,alarm-limit-r12 = <0x9999>;
                        xlnx,edk-iptype = "PERIPHERAL";
                        xlnx,alarm-limit-r13 = <0x91eb>;
                        xlnx,sequencer-mode;
                        xlnx,enable-jtagbusy;
                        xlnx,alarm-limit-r14 = <0x6aaa>;
                        xlnx,include-intr = <0x1>;
                        xlnx,alarm-limit-r15 = <0x6222>;
                        xlnx,fifo-depth = <0x7>;
                        xlnx,has-eoc = <0x1>;
                        xlnx,temperature-alarm-ot-trigger = <0x7d>;
                        xlnx,has-channel = <0x1>;
                        xlnx,enable-eos;
                        xlnx,vccpint-alarm-lower = <0xe7ef0>;
                        xlnx,vccint-alarm-lower = <0xecd10>;
                        xlnx,has-dclk = <0x1>;
                        xlnx,vbram-alarm-lower = <0xe7ef0>;
                        xlnx,num-wave = <0x1>;
                        xlnx,sequence-r0 = <0x100>;
                        xlnx,has-jtagmodified = <0x0>;
                        xlnx,sequence-r1 = <0x0>;
                        xlnx,enable-drp;
                        xlnx,sequence-r2 = <0x0>;
                        xlnx,has-vccint-alarm = <0x1>;
                        xlnx,channel-averaging = "None";
                        xlnx,sequence-r3 = <0x0>;
                        xlnx,has-axi4stream = <0x1>;
                        xlnx,sequence-r4 = <0x0>;
                        xlnx,sequence-r5 = <0x0>;
                        xlnx,adc-offset-and-gain-calibration;
                        xlnx,waveform-type = "CONSTANT";
                        xlnx,sequence-r6 = <0x0>;
                        xlnx,vccddro-volt = "1_2";
                        xlnx,sequence-r7 = <0x0>;
                        xlnx,has-vccddro-alarm = <0x0>;
                        xlnx,alarm-limit-r0 = <0xb5ed>;
                        xlnx,has-convstclk = <0x0>;
                        xlnx,has-eos = <0x1>;
                        xlnx,stimulus-freq = <0x1>;
                        xlnx,single-channel-enable-calibration;
                        xlnx,alarm-limit-r1 = <0x57e4>;
                        xlnx,component-name = "design_1_xadc_wiz_0_0";
                        xlnx,external-muxaddr-enable = <0x0>;
                        phandle = <0x14>;
                };
        };

        axi_bram_ctrl_0_memory: memory@c0000000 {
                compatible = "xlnx,axi-bram-ctrl-4.1";
                xlnx,ip-name = "axi_bram_ctrl";
                device_type = "memory";
                memory_type = "memory";
                reg = <0xc0000000 0x2000>;
                phandle = <0x1>;
        };

        microblaze_0_local_memory_dlmb_bram_if_cntlr_memory: memory@0 {
                compatible = "xlnx,lmb-bram-if-cntlr-4.0";
                xlnx,ip-name = "lmb_bram_if_cntlr";
                device_type = "memory";
                memory_type = "memory";
                reg = <0x0 0x10000>;
                phandle = <0x3>;
        };

        chosen {
                stdout-path = "serial0:115200n8";
        };

        aliases {
                serial0 = "/amba_pl/serial@40600000";
        };

        __symbols__ {
                cpus_microblaze_0 = "/cpus_microblaze@0";
                microblaze_0 = "/cpus_microblaze@0/cpu@0";
                clock = "/clocks";
                clk_cpu_0 = "/clocks/clk_cpu@0";
                clk_bus_0 = "/clocks/clk_bus_0@1";
                amba_pl = "/amba_pl";
                microblaze_0_axi_intc = "/amba_pl/interrupt-controller@41200000";
                axi_bram_ctrl_0 = "/amba_pl/axi_bram_ctrl_0@c0000000";
                axi_dma_0 = "/amba_pl/dma@41e00000";
                dma_channel_41e00030 = "/amba_pl/dma@41e00000/dma-channel@41e00030";
                axi_gpio_0 = "/amba_pl/gpio@40000000";
                axi_gpio_1 = "/amba_pl/gpio@40010000";
                axi_gpio_10 = "/amba_pl/gpio@400b0000";
                axi_gpio_2 = "/amba_pl/gpio@40020000";
                axi_gpio_3 = "/amba_pl/gpio@40040000";
                axi_gpio_4 = "/amba_pl/gpio@40050000";
                axi_gpio_5 = "/amba_pl/gpio@40060000";
                axi_gpio_6 = "/amba_pl/gpio@40070000";
                axi_gpio_7 = "/amba_pl/gpio@40080000";
                axi_gpio_8 = "/amba_pl/gpio@40090000";
                axi_gpio_9 = "/amba_pl/gpio@400a0000";
                axi_gpio_irq_spi = "/amba_pl/gpio@40030000";
                axi_uartlite_0 = "/amba_pl/serial@40600000";
                microblaze_0_local_memory_dlmb_bram_if_cntlr = "/amba_pl/lmb_bram_if_cntlr@0";
                microblaze_0_local_memory_ilmb_bram_if_cntlr = "/amba_pl/lmb_bram_if_cntlr@1";
                xadc_wiz_0 = "/amba_pl/xadc_wiz@44a00000";
                axi_bram_ctrl_0_memory = "/memory@c0000000";
                microblaze_0_local_memory_dlmb_bram_if_cntlr_memory = "/memory@0";
        };
};
